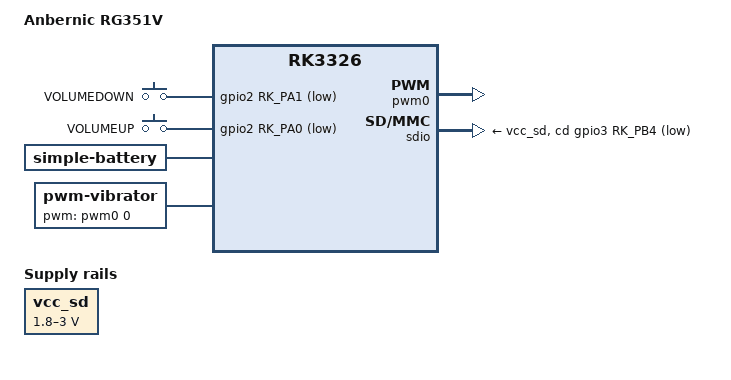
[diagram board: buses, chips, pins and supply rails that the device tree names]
// SPDX-License-Identifier: (GPL-2.0+ OR MIT)
/*
 * Copyright (c) 2019 Hardkernel Co., Ltd
 * Copyright (c) 2020 Theobroma Systems Design und Consulting GmbH
 * Copyright (c) 2022 Maya Matuszczyk <maccraft123mc@gmail.com>
 */

/dts-v1/;
#include "rk3326-odroid-go.dtsi"

/ {
	model = "Anbernic RG351V";
	compatible = "anbernic,rg351v", "rockchip,rk3326";

       aliases {
               mmc0 = &sdio;
               mmc1 = &sdmmc;
       };

        gpio-keys-vol {
                compatible = "gpio-keys";
                autorepeat;
                pinctrl-0 = <&btn_pins_vol>;
                pinctrl-names = "default";

                button-vol-down {
                        gpios = <&gpio2 RK_PA1 GPIO_ACTIVE_LOW>;
                        label = "VOLUMEDOWN";
                        linux,code = <KEY_VOLUMEDOWN>;
                };

                button-volume-up {
                        gpios = <&gpio2 RK_PA0 GPIO_ACTIVE_LOW>;
                        label = "VOLUMEUP";
                        linux,code = <KEY_VOLUMEUP>;
                };
        };

        battery: battery {
               compatible = "simple-battery";
               charge-full-design-microamp-hours = <3500000>;
               charge-term-current-microamp = <350000>;
               constant-charge-current-max-microamp = <2000000>;
               constant-charge-voltage-max-microvolt = <4200000>;
               factory-internal-resistance-micro-ohms = <180000>;
               voltage-max-design-microvolt = <4100000>;
               voltage-min-design-microvolt = <3500000>;

               ocv-capacity-celsius = <20>;
               ocv-capacity-table-0 =  <4046950 100>, <4001920 95>, <3967900 90>, <3919950 85>,
                                       <3888450 80>, <3861850 75>, <3831540 70>, <3799130 65>,
                                       <3768190 60>, <3745650 55>, <3726610 50>, <3711630 45>,
                                       <3696720 40>, <3685660 35>, <3674950 30>, <3663050 25>,
                                       <3649470 20>, <3635260 15>, <3616920 10>, <3592440 5>,
                                       <3574170 0>;
       };

	vibrator {
		compatible = "pwm-vibrator";
		pwms = <&pwm0 0 1000000 0>;
		pwm-names = "enable";
	};
};

/* conflicts with pwm vibration motor */
/delete-node/ &vcc_host;

/* Device only has 1 LED compared to Odroid Go Advance */
/delete-node/ &gpio_led;

&internal_display {
	compatible = "anbernic,rg351v-panel", "newvision,nv3051d";
	iovcc-supply = <&vcc_lcd>;
	vdd-supply = <&vcc_lcd>;
};

&io_domains {
	vccio1-supply = <&vccio_sd>;
};

/delete-node/ &pwm_led;

&pwm0 {
	status = "okay";
};

/delete-node/ &pwm3;

&rk817_charger {
       /* This device does not have a current sense resistor */
       rockchip,resistor-sense-micro-ohms = <0>;
       monitored-battery = <&battery>;
};

&sdio {
	cap-sd-highspeed;
	card-detect-delay = <200>;
	cd-gpios = <&gpio3 RK_PB4 GPIO_ACTIVE_LOW>; /*[> CD GPIO <]*/
	sd-uhs-sdr12;
	sd-uhs-sdr25;
	sd-uhs-sdr50;
	sd-uhs-sdr104;
	vmmc-supply = <&vcc_sd>;
	vqmmc-supply = <&vccio_sd>;
	status = "okay";
};

&vcc_sd {
	regulator-max-microvolt = <3000000>;
	regulator-min-microvolt = <1800000>;
};

&vccio_sd {
	regulator-max-microvolt = <1800000>;
};

&pinctrl {
        btns {
                btn_pins_vol: btn-pins-vol {
                        rockchip,pins = <2 RK_PA0 RK_FUNC_GPIO &pcfg_pull_up>,
                                        <2 RK_PA1 RK_FUNC_GPIO &pcfg_pull_up>;
                };
        };
};
